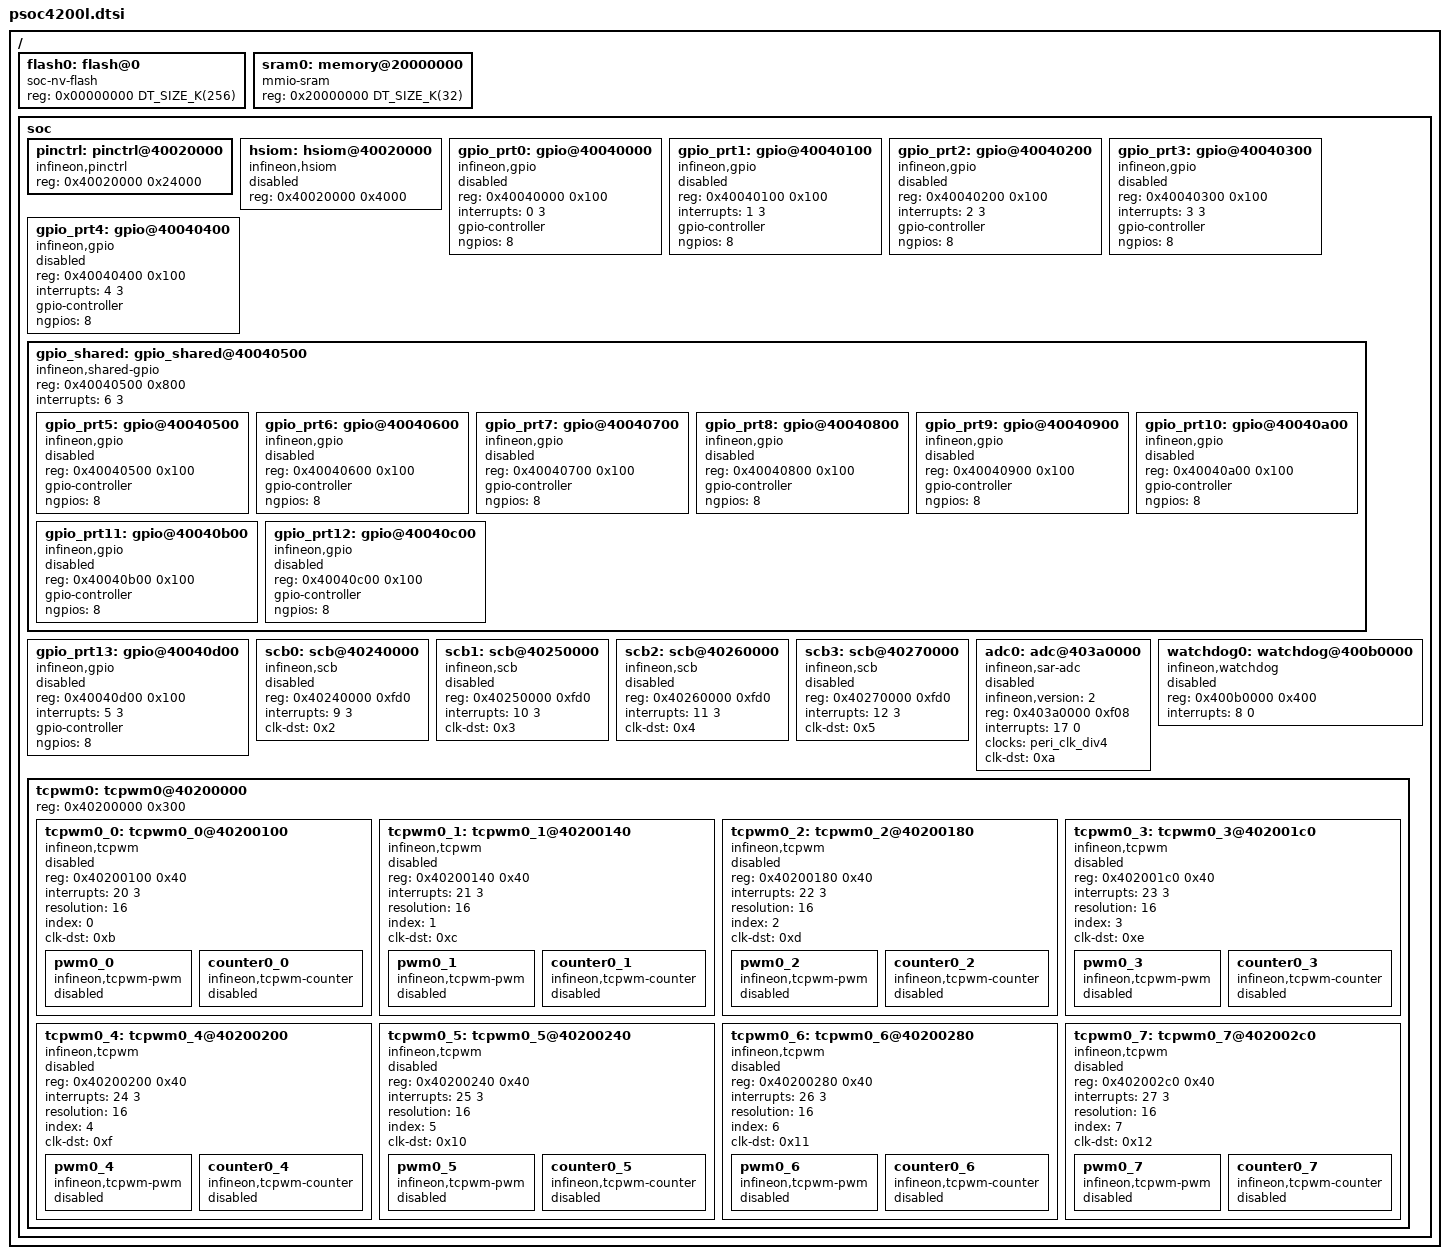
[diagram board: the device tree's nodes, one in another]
/*
 * Copyright (c) 2025 PSoC 4200L Zephyr Port
 * SPDX-License-Identifier: Apache-2.0
 *
 * PSoC 4200L peripheral definitions.
 * Register addresses from cydevice_trm.h (CY8C4248LTI-L475).
 * IRQ numbers from TRM Table 6-2.
 * clk-dst values from TRM Table 8-16.
 */

#include <mem.h>
#include "psoc4200l.cm0.dtsi"
#include <zephyr/dt-bindings/gpio/gpio.h>

/ {
	flash0: flash@0 {
		compatible = "soc-nv-flash";
		reg = <0x00000000 DT_SIZE_K(256)>;
	};

	sram0: memory@20000000 {
		compatible = "mmio-sram";
		reg = <0x20000000 DT_SIZE_K(32)>;
	};

	soc {
		pinctrl: pinctrl@40020000 {
			compatible = "infineon,pinctrl";
			reg = <0x40020000 0x24000>;
		};

		hsiom: hsiom@40020000 {
			compatible = "infineon,hsiom";
			reg = <0x40020000 0x4000>;
			status = "disabled";
		};

		/* GPIO Ports 0-4: dedicated interrupts (IRQ 0-4) */
		gpio_prt0: gpio@40040000 {
			compatible = "infineon,gpio";
			reg = <0x40040000 0x100>;
			interrupts = <0 3>;
			gpio-controller;
			ngpios = <8>;
			status = "disabled";
			#gpio-cells = <2>;
		};

		gpio_prt1: gpio@40040100 {
			compatible = "infineon,gpio";
			reg = <0x40040100 0x100>;
			interrupts = <1 3>;
			gpio-controller;
			ngpios = <8>;
			status = "disabled";
			#gpio-cells = <2>;
		};

		gpio_prt2: gpio@40040200 {
			compatible = "infineon,gpio";
			reg = <0x40040200 0x100>;
			interrupts = <2 3>;
			gpio-controller;
			ngpios = <8>;
			status = "disabled";
			#gpio-cells = <2>;
		};

		gpio_prt3: gpio@40040300 {
			compatible = "infineon,gpio";
			reg = <0x40040300 0x100>;
			interrupts = <3 3>;
			gpio-controller;
			ngpios = <8>;
			status = "disabled";
			#gpio-cells = <2>;
		};

		gpio_prt4: gpio@40040400 {
			compatible = "infineon,gpio";
			reg = <0x40040400 0x100>;
			interrupts = <4 3>;
			gpio-controller;
			ngpios = <8>;
			status = "disabled";
			#gpio-cells = <2>;
		};

		/* Ports 5-12 share IRQ 6 (ioss_interrupt_gpio_IRQn) */
		gpio_shared: gpio_shared@40040500 {
			compatible = "infineon,shared-gpio";
			reg = <0x40040500 0x800>;
			#address-cells = <1>;
			#size-cells = <1>;
			interrupts = <6 3>;

			gpio_prt5: gpio@40040500 {
				compatible = "infineon,gpio";
				reg = <0x40040500 0x100>;
				gpio-controller;
				ngpios = <8>;
				status = "disabled";
				#gpio-cells = <2>;
			};

			gpio_prt6: gpio@40040600 {
				compatible = "infineon,gpio";
				reg = <0x40040600 0x100>;
				gpio-controller;
				ngpios = <8>;
				status = "disabled";
				#gpio-cells = <2>;
			};

			gpio_prt7: gpio@40040700 {
				compatible = "infineon,gpio";
				reg = <0x40040700 0x100>;
				gpio-controller;
				ngpios = <8>;
				status = "disabled";
				#gpio-cells = <2>;
			};

			gpio_prt8: gpio@40040800 {
				compatible = "infineon,gpio";
				reg = <0x40040800 0x100>;
				gpio-controller;
				ngpios = <8>;
				status = "disabled";
				#gpio-cells = <2>;
			};

			gpio_prt9: gpio@40040900 {
				compatible = "infineon,gpio";
				reg = <0x40040900 0x100>;
				gpio-controller;
				ngpios = <8>;
				status = "disabled";
				#gpio-cells = <2>;
			};

			gpio_prt10: gpio@40040a00 {
				compatible = "infineon,gpio";
				reg = <0x40040a00 0x100>;
				gpio-controller;
				ngpios = <8>;
				status = "disabled";
				#gpio-cells = <2>;
			};

			gpio_prt11: gpio@40040b00 {
				compatible = "infineon,gpio";
				reg = <0x40040b00 0x100>;
				gpio-controller;
				ngpios = <8>;
				status = "disabled";
				#gpio-cells = <2>;
			};

			gpio_prt12: gpio@40040c00 {
				compatible = "infineon,gpio";
				reg = <0x40040c00 0x100>;
				gpio-controller;
				ngpios = <8>;
				status = "disabled";
				#gpio-cells = <2>;
			};
		};

		/* Port 13: dedicated IRQ 5 (USB wakeup) */
		gpio_prt13: gpio@40040d00 {
			compatible = "infineon,gpio";
			reg = <0x40040d00 0x100>;
			interrupts = <5 3>;
			gpio-controller;
			ngpios = <8>;
			status = "disabled";
			#gpio-cells = <2>;
		};

		/* SCB 0-3: IRQ 9-12, clk-dst 2-5 */
		scb0: scb@40240000 {
			compatible = "infineon,scb";
			reg = <0x40240000 0xfd0>;
			interrupts = <9 3>;
			clk-dst = <0x2>;
			status = "disabled";
		};

		scb1: scb@40250000 {
			compatible = "infineon,scb";
			reg = <0x40250000 0xfd0>;
			interrupts = <10 3>;
			clk-dst = <0x3>;
			status = "disabled";
		};

		scb2: scb@40260000 {
			compatible = "infineon,scb";
			reg = <0x40260000 0xfd0>;
			interrupts = <11 3>;
			clk-dst = <0x4>;
			status = "disabled";
		};

		scb3: scb@40270000 {
			compatible = "infineon,scb";
			reg = <0x40270000 0xfd0>;
			interrupts = <12 3>;
			clk-dst = <0x5>;
			status = "disabled";
		};

		/* SAR ADC: IRQ 17, clk-dst 0xA */
		adc0: adc@403a0000 {
			compatible = "infineon,sar-adc";
			infineon,version = <2>;
			reg = <0x403a0000 0xf08>;
			interrupts = <17 0>;
			#io-channel-cells = <1>;
			clocks = <&peri_clk_div4>;
			clk-dst = <0xa>;
			status = "disabled";
		};

		/* Watchdog: SRSS @ 0x400B0000, IRQ 8 */
		watchdog0: watchdog@400b0000 {
			compatible = "infineon,watchdog";
			reg = <0x400b0000 0x400>;
			interrupts = <8 0>;
			status = "disabled";
		};

		/* TCPWM 0-7: IRQ 20-27, clk-dst 0xB-0x12 */
		tcpwm0: tcpwm0@40200000 {
			reg = <0x40200000 0x300>;
			#address-cells = <1>;
			#size-cells = <1>;

			tcpwm0_0: tcpwm0_0@40200100 {
				compatible = "infineon,tcpwm";
				reg = <0x40200100 0x40>;
				interrupts = <20 3>;
				resolution = <16>;
				index = <0>;
				clk-dst = <0xb>;
				status = "disabled";

				pwm0_0: pwm0_0 {
					compatible = "infineon,tcpwm-pwm";
					#pwm-cells = <3>;
					status = "disabled";
				};

				counter0_0: counter0_0 {
					compatible = "infineon,tcpwm-counter";
					status = "disabled";
				};
			};

			tcpwm0_1: tcpwm0_1@40200140 {
				compatible = "infineon,tcpwm";
				reg = <0x40200140 0x40>;
				interrupts = <21 3>;
				resolution = <16>;
				index = <1>;
				clk-dst = <0xc>;
				status = "disabled";

				pwm0_1: pwm0_1 {
					compatible = "infineon,tcpwm-pwm";
					#pwm-cells = <3>;
					status = "disabled";
				};

				counter0_1: counter0_1 {
					compatible = "infineon,tcpwm-counter";
					status = "disabled";
				};
			};

			tcpwm0_2: tcpwm0_2@40200180 {
				compatible = "infineon,tcpwm";
				reg = <0x40200180 0x40>;
				interrupts = <22 3>;
				resolution = <16>;
				index = <2>;
				clk-dst = <0xd>;
				status = "disabled";

				pwm0_2: pwm0_2 {
					compatible = "infineon,tcpwm-pwm";
					#pwm-cells = <3>;
					status = "disabled";
				};

				counter0_2: counter0_2 {
					compatible = "infineon,tcpwm-counter";
					status = "disabled";
				};
			};

			tcpwm0_3: tcpwm0_3@402001c0 {
				compatible = "infineon,tcpwm";
				reg = <0x402001c0 0x40>;
				interrupts = <23 3>;
				resolution = <16>;
				index = <3>;
				clk-dst = <0xe>;
				status = "disabled";

				pwm0_3: pwm0_3 {
					compatible = "infineon,tcpwm-pwm";
					#pwm-cells = <3>;
					status = "disabled";
				};

				counter0_3: counter0_3 {
					compatible = "infineon,tcpwm-counter";
					status = "disabled";
				};
			};

			tcpwm0_4: tcpwm0_4@40200200 {
				compatible = "infineon,tcpwm";
				reg = <0x40200200 0x40>;
				interrupts = <24 3>;
				resolution = <16>;
				index = <4>;
				clk-dst = <0xf>;
				status = "disabled";

				pwm0_4: pwm0_4 {
					compatible = "infineon,tcpwm-pwm";
					#pwm-cells = <3>;
					status = "disabled";
				};

				counter0_4: counter0_4 {
					compatible = "infineon,tcpwm-counter";
					status = "disabled";
				};
			};

			tcpwm0_5: tcpwm0_5@40200240 {
				compatible = "infineon,tcpwm";
				reg = <0x40200240 0x40>;
				interrupts = <25 3>;
				resolution = <16>;
				index = <5>;
				clk-dst = <0x10>;
				status = "disabled";

				pwm0_5: pwm0_5 {
					compatible = "infineon,tcpwm-pwm";
					#pwm-cells = <3>;
					status = "disabled";
				};

				counter0_5: counter0_5 {
					compatible = "infineon,tcpwm-counter";
					status = "disabled";
				};
			};

			tcpwm0_6: tcpwm0_6@40200280 {
				compatible = "infineon,tcpwm";
				reg = <0x40200280 0x40>;
				interrupts = <26 3>;
				resolution = <16>;
				index = <6>;
				clk-dst = <0x11>;
				status = "disabled";

				pwm0_6: pwm0_6 {
					compatible = "infineon,tcpwm-pwm";
					#pwm-cells = <3>;
					status = "disabled";
				};

				counter0_6: counter0_6 {
					compatible = "infineon,tcpwm-counter";
					status = "disabled";
				};
			};

			tcpwm0_7: tcpwm0_7@402002c0 {
				compatible = "infineon,tcpwm";
				reg = <0x402002c0 0x40>;
				interrupts = <27 3>;
				resolution = <16>;
				index = <7>;
				clk-dst = <0x12>;
				status = "disabled";

				pwm0_7: pwm0_7 {
					compatible = "infineon,tcpwm-pwm";
					#pwm-cells = <3>;
					status = "disabled";
				};

				counter0_7: counter0_7 {
					compatible = "infineon,tcpwm-counter";
					status = "disabled";
				};
			};
		};
	};
};
